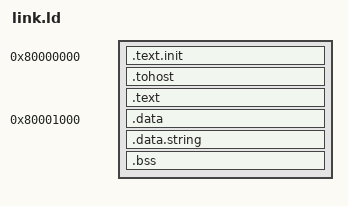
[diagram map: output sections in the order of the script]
OUTPUT_ARCH( "riscv" )
ENTRY(main)

SECTIONS
{
  . = 0x80000000;
  .text.init : { *(.text.init) }
  . = ALIGN(0x1000);
  .tohost : { *(.tohost) }
  . = ALIGN(0x1000);
  .text : { *(.text) }
  . = 0x80001000; /* Set the start address for data section */
  .data : { *(.data) }
  .data.string : { *(.data.string)}
  .bss : { *(.bss) }
  _end = .;
}

